# BL808 register map
File version: 0.1
Registers are access not given, no defined reset value unless marked. A register's access mark holds for its fields unless they carry their own. Offsets are from the block's base; [hi:lo] are bit positions; {n}, {i} and the like mark numbered series.

## OSD_A_DRAW_LAYER_L
Base 0x30013400
Same registers: OSD_B_DRAW_LAYER_L 0x30014400, OSD_DP_DRAW_LAYER_L 0x30015400
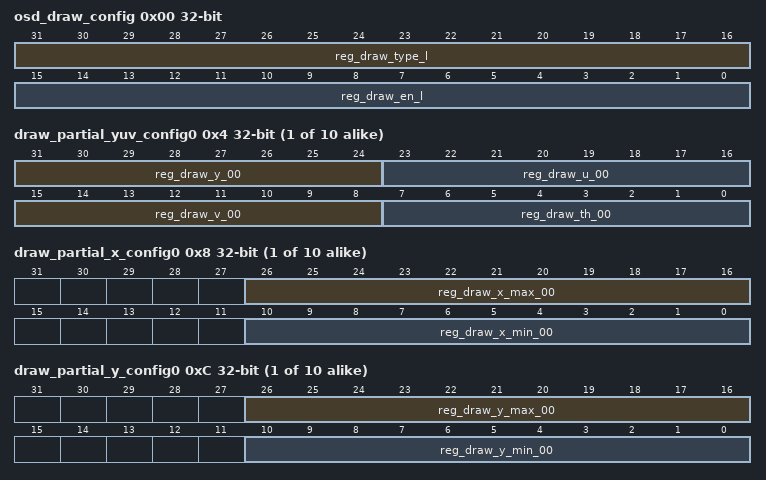
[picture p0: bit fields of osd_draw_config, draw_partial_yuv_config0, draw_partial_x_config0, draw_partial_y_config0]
0x00 osd_draw_config rw
  [31:16] reg_draw_type_l, [15:0] reg_draw_en_l
{0x4+0xC*i} draw_partial_yuv_config{i} rw (i=0..9)
  [31:24] reg_draw_y_{i:02}, [23:16] reg_draw_u_{i:02}, [15:8] reg_draw_v_{i:02}, [7:0] reg_draw_th_{i:02}
{0x8+0xC*i} draw_partial_x_config{i} (i=0..9)
  [26:16] reg_draw_x_max_{i:02} rw, [10:0] reg_draw_x_min_{i:02} rw
{0xC+0xC*i} draw_partial_y_config{i} (i=0..9)
  [26:16] reg_draw_y_max_{i:02} rw, [10:0] reg_draw_y_min_{i:02} rw
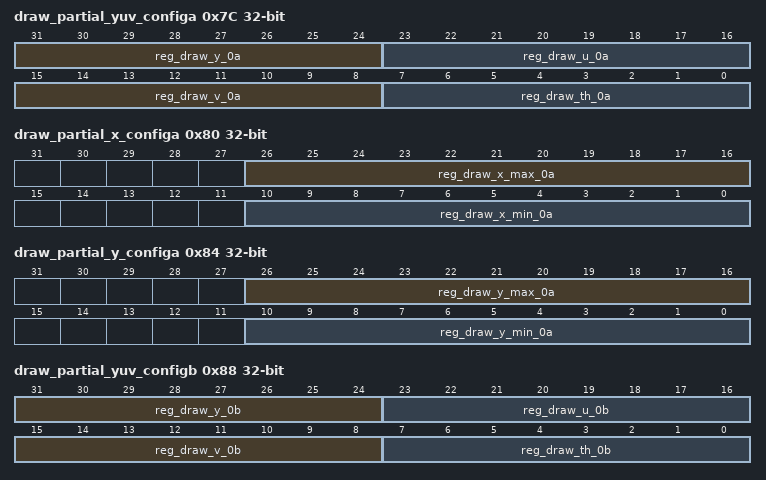
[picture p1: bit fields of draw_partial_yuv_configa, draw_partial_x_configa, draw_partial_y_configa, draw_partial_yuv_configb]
0x7C draw_partial_yuv_configa rw
  [31:24] reg_draw_y_0a, [23:16] reg_draw_u_0a, [15:8] reg_draw_v_0a, [7:0] reg_draw_th_0a
0x80 draw_partial_x_configa
  [26:16] reg_draw_x_max_0a rw, [10:0] reg_draw_x_min_0a rw
0x84 draw_partial_y_configa
  [26:16] reg_draw_y_max_0a rw, [10:0] reg_draw_y_min_0a rw
0x88 draw_partial_yuv_configb rw
  [31:24] reg_draw_y_0b, [23:16] reg_draw_u_0b, [15:8] reg_draw_v_0b, [7:0] reg_draw_th_0b
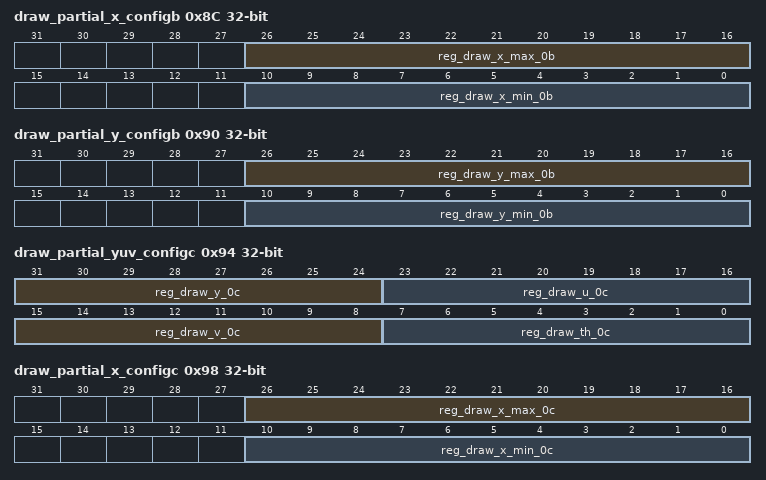
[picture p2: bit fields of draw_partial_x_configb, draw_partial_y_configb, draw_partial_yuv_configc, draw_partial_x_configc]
0x8C draw_partial_x_configb
  [26:16] reg_draw_x_max_0b rw, [10:0] reg_draw_x_min_0b rw
0x90 draw_partial_y_configb
  [26:16] reg_draw_y_max_0b rw, [10:0] reg_draw_y_min_0b rw
0x94 draw_partial_yuv_configc rw
  [31:24] reg_draw_y_0c, [23:16] reg_draw_u_0c, [15:8] reg_draw_v_0c, [7:0] reg_draw_th_0c
0x98 draw_partial_x_configc
  [26:16] reg_draw_x_max_0c rw, [10:0] reg_draw_x_min_0c rw
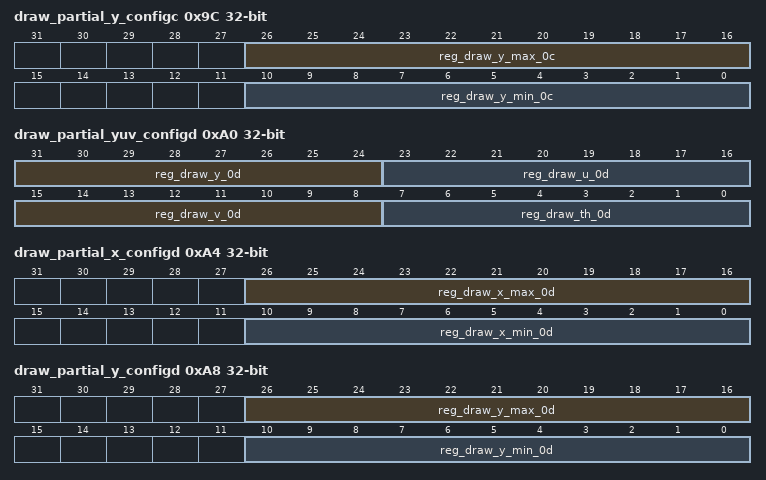
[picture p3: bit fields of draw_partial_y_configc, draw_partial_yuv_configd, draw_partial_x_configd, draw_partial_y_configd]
0x9C draw_partial_y_configc
  [26:16] reg_draw_y_max_0c rw, [10:0] reg_draw_y_min_0c rw
0xA0 draw_partial_yuv_configd rw
  [31:24] reg_draw_y_0d, [23:16] reg_draw_u_0d, [15:8] reg_draw_v_0d, [7:0] reg_draw_th_0d
0xA4 draw_partial_x_configd
  [26:16] reg_draw_x_max_0d rw, [10:0] reg_draw_x_min_0d rw
0xA8 draw_partial_y_configd
  [26:16] reg_draw_y_max_0d rw, [10:0] reg_draw_y_min_0d rw
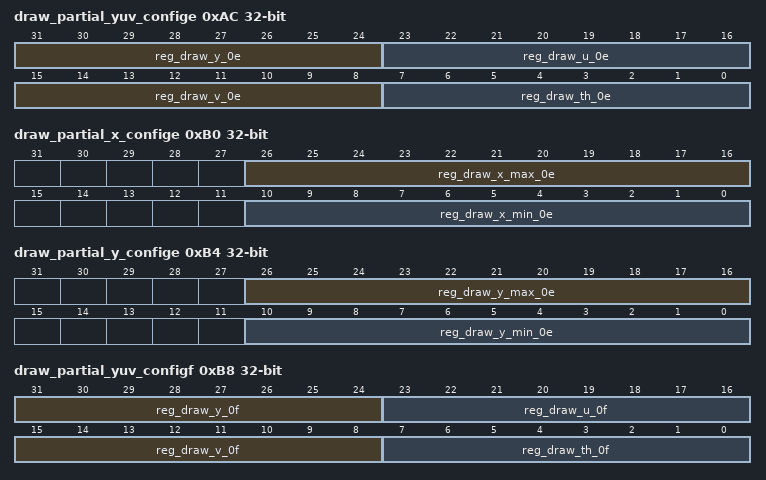
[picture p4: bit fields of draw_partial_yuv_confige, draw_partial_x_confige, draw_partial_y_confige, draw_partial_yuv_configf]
0xAC draw_partial_yuv_confige rw
  [31:24] reg_draw_y_0e, [23:16] reg_draw_u_0e, [15:8] reg_draw_v_0e, [7:0] reg_draw_th_0e
0xB0 draw_partial_x_confige
  [26:16] reg_draw_x_max_0e rw, [10:0] reg_draw_x_min_0e rw
0xB4 draw_partial_y_confige
  [26:16] reg_draw_y_max_0e rw, [10:0] reg_draw_y_min_0e rw
0xB8 draw_partial_yuv_configf rw
  [31:24] reg_draw_y_0f, [23:16] reg_draw_u_0f, [15:8] reg_draw_v_0f, [7:0] reg_draw_th_0f
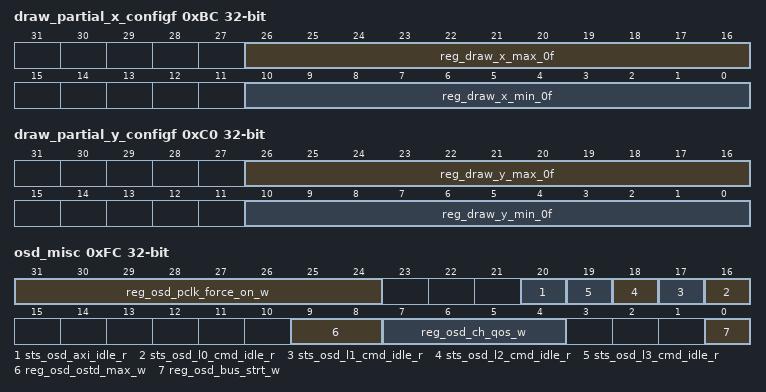
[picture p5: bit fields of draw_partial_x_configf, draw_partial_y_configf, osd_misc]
0xBC draw_partial_x_configf
  [26:16] reg_draw_x_max_0f rw, [10:0] reg_draw_x_min_0f rw
0xC0 draw_partial_y_configf
  [26:16] reg_draw_y_max_0f rw, [10:0] reg_draw_y_min_0f rw
0xFC osd_misc
  [31:24] reg_osd_pclk_force_on_w rw, [20] sts_osd_axi_idle_r ro, [n+16] sts_osd_l{n}_cmd_idle_r ro (n=0..3), [9:8] reg_osd_ostd_max_w rw, [7:4] reg_osd_ch_qos_w rw, [0] reg_osd_bus_strt_w write-once

## OSD_PROBE
Base 0x30012B00
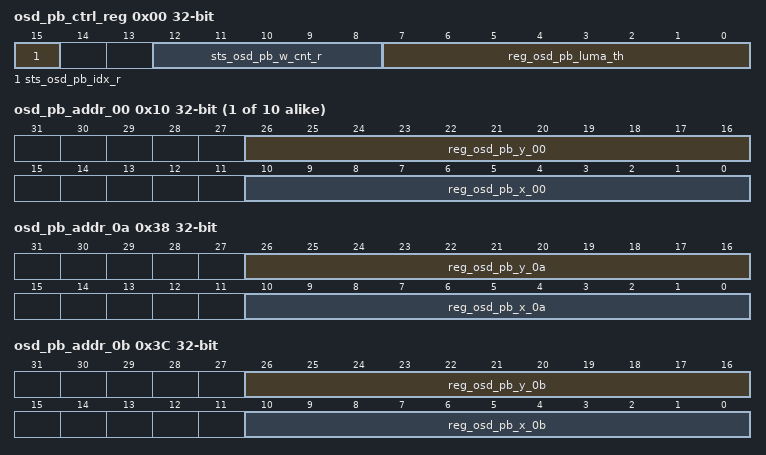
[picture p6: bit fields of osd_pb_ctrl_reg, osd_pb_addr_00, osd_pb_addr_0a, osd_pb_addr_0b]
0x00 osd_pb_ctrl_reg
  [15] sts_osd_pb_idx_r ro, [12:8] sts_osd_pb_w_cnt_r ro, [7:0] reg_osd_pb_luma_th rw
0x04 osd_pb_result0 ro
  [31:0] sts_osd_pb_result_0_r
0x08 osd_pb_result1 ro
  [31:0] sts_osd_pb_result_1_r
{0x10+4i} osd_pb_addr_{i:02} (i=0..9)
  [26:16] reg_osd_pb_y_{i:02} rw, [10:0] reg_osd_pb_x_{i:02} rw
0x38 osd_pb_addr_0a
  [26:16] reg_osd_pb_y_0a rw, [10:0] reg_osd_pb_x_0a rw
0x3C osd_pb_addr_0b
  [26:16] reg_osd_pb_y_0b rw, [10:0] reg_osd_pb_x_0b rw
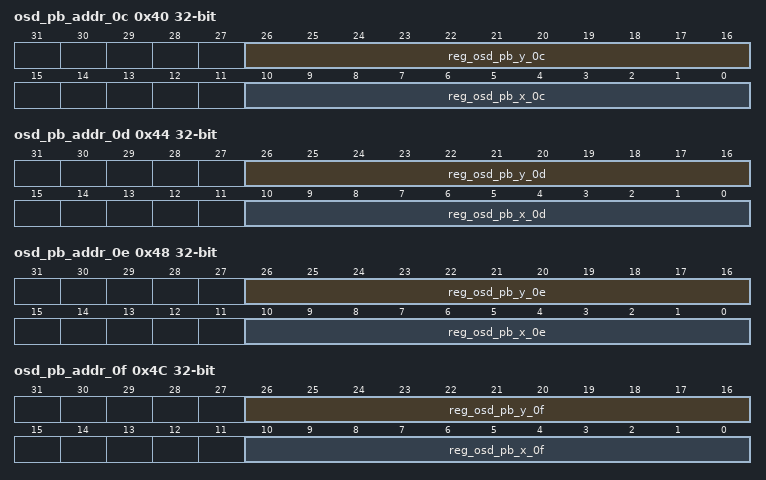
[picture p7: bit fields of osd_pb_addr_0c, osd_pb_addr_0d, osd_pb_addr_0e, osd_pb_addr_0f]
0x40 osd_pb_addr_0c
  [26:16] reg_osd_pb_y_0c rw, [10:0] reg_osd_pb_x_0c rw
0x44 osd_pb_addr_0d
  [26:16] reg_osd_pb_y_0d rw, [10:0] reg_osd_pb_x_0d rw
0x48 osd_pb_addr_0e
  [26:16] reg_osd_pb_y_0e rw, [10:0] reg_osd_pb_x_0e rw
0x4C osd_pb_addr_0f
  [26:16] reg_osd_pb_y_0f rw, [10:0] reg_osd_pb_x_0f rw
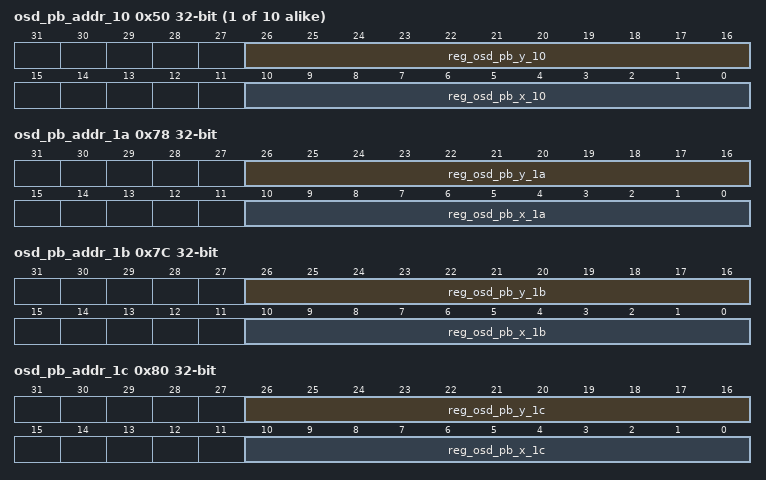
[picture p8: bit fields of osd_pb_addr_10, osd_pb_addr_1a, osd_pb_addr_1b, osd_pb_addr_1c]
{0x28+4i} osd_pb_addr_{i} (i=10..19)
  [26:16] reg_osd_pb_y_{i} rw, [10:0] reg_osd_pb_x_{i} rw
0x78 osd_pb_addr_1a
  [26:16] reg_osd_pb_y_1a rw, [10:0] reg_osd_pb_x_1a rw
0x7C osd_pb_addr_1b
  [26:16] reg_osd_pb_y_1b rw, [10:0] reg_osd_pb_x_1b rw
0x80 osd_pb_addr_1c
  [26:16] reg_osd_pb_y_1c rw, [10:0] reg_osd_pb_x_1c rw
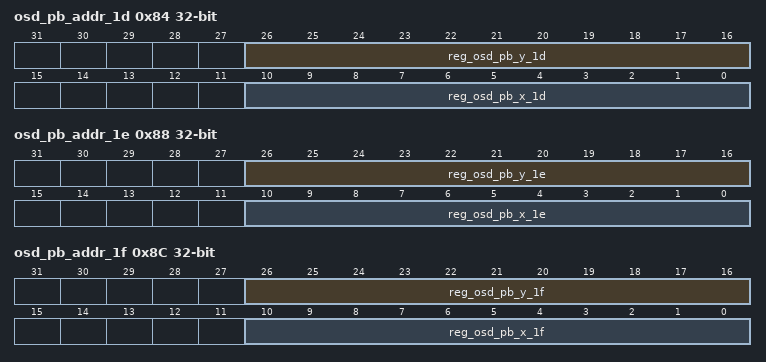
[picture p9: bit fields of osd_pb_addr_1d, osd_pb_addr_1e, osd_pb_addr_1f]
0x84 osd_pb_addr_1d
  [26:16] reg_osd_pb_y_1d rw, [10:0] reg_osd_pb_x_1d rw
0x88 osd_pb_addr_1e
  [26:16] reg_osd_pb_y_1e rw, [10:0] reg_osd_pb_x_1e rw
0x8C osd_pb_addr_1f
  [26:16] reg_osd_pb_y_1f rw, [10:0] reg_osd_pb_x_1f rw
